# LPC55S16 register map
Vendor: nxp.com; File version: 1.0
CPU: CM33 r2p0, little endian, MPU, FPU, VTOR, 3 interrupt priority bits
Registers are 32-bit, read-write, reset 0x0 unless marked. A register's access mark holds for its fields unless they carry their own. Offsets are from the block's base; [hi:lo] are bit positions; {n}, {i} and the like mark numbered series; 'fields as' and 'values as' point back to an identical list.

## HASHCRYPT — Hash-Crypt peripheral
Base 0x400A4000
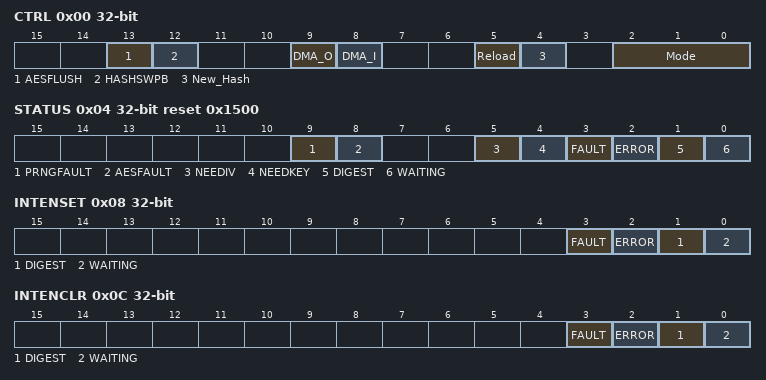
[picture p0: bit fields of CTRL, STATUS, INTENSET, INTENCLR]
0x00 CTRL — Control register to enable and operate Hash and Crypto
  [13] AESFLUSH wo — Flushes the AES engine registers. This bit self clears.
    0=NOFLUSH (Do not flush the AES engine registers.); 1=FLUSH (Flush the AES engine registers.)
  [12] HASHSWPB — If 1, will swap bytes in the word for SHA hashing. The default is byte order (so LSB is 1st byte) but this allows swapping to MSB is 1st such as is shown in SHS spec. For cryptographic swapping, see the CRYPTCFG register.
  [9] DMA_O — Written to 1 to use DMA to drain the digest/output. If both DMA_I and DMA_O are set, the DMA has to know to switch direction and the locations. This can be used for crypto uses.
    0=NOTUSED (DMA is not used. Processor reads the digest/output in response to DIGEST interrupt.)
  [8] DMA_I — Written with 1 to use DMA to fill INDATA. If Hash, will request from DMA for 16 words and then will process the Hash. If Cryptographic, it will load as many words as needed, including key if not already loaded. It will then request again. Normal model is that the DMA interrupts the processor when its length expires. Note that if the processor will write the key and optionally IV, it should not enable this until it has done so. Otherwise, the DMA will be expected to load those for the 1st block (when needed).
    0=NOT_USED (DMA is not used. Processor writes the necessary words when WAITING is set (interrupts), unless AHB Master is used.); 1=PUSH (DMA will push in the data.)
  [5] Reload — If 1, allows the SHA RELOAD registers to be used. This is used to save a partial Hash Digest (e.g. when need to run AES) and then reload it later for continuation.
    1=RELOAD (Allow RELOAD registers to be used.)
  [4] New_Hash wo — Written with 1 when starting a new Hash/Crypto. It self clears. Note that the WAITING Status bit will clear for a cycle during the initialization from New=1.
    1=START (Starts a new Hash/Crypto and initializes the Digest/Result.)
  [2:0] Mode — The operational mode to use, or 0 if none. Note that the CONFIG register will indicate if specific modes beyond SHA1 and SHA2-256 are available.
    0=DISABLED; 1=SHA1 (SHA1 is enabled); 2=SHA2_256 (SHA2-256 is enabled); 4=AES (AES if available (see also CRYPTCFG register for more controls))
0x04 STATUS reset 0x1500 (reset mask 0x3F3737) — Indicates status of Hash peripheral.
  [9] PRNGFAULT ro — PRNG fault status
    0=NO_FAULT (No PRNG fault has occurred.); 1=FAULT (A PRNG fault has occurred.)
  [8] AESFAULT ro — AES fault status
    0=NO_FAULT (No AES fault has occurred.); 1=FAULT (An AES fault has occurred.)
  [5] NEEDIV ro — Indicates the block wants an IV/NONE to be written in (set along with WAITING)
    0=NOT_NEED (No IV/Nonce is needed, either because written already or because not needed.); 1=NEED (IV/Nonce is needed and INDATA/ALIAS will be accepted as IV/Nonce. Will also set WAITING.)
  [4] NEEDKEY ro — Indicates the block wants the key to be written in (set along with WAITING)
    0=NOT_NEED (No Key is needed and writes will not be treated as Key); 1=NEED (Key is needed and INDATA/ALIAS will be accepted as Key. Will also set WAITING.)
  [3] FAULT ro — Indicates if an AES or PRNG fault has occurred
    0=NO_FAULT (No AES or PRNG fault has occurred.); 1=FAULT (An AES or PRNG fault has occurred.)
  [2] ERROR write-1-clears — If 1, an error occurred. For normal uses, this is due to an attempted overrun: INDATA was written when it was not appropriate. For Master cases, this is an AHB bus error; the COUNT field will indicate which block it was on.
    0=NO_ERROR; 1=ERROR (An error occurred since last cleared (written 1 to clear).)
  [1] DIGEST ro — For Hash, if 1 then a DIGEST is ready and waiting and there is no active next block already started. For Cryptographic uses, this will be set for each block processed, indicating OUTDATA (and OUTDATA2 if larger output) contains the next value to read out. This is cleared when any data is written, when New is written, for Cryptographic uses when the last word is read out, or when the block is disabled.
    0=NOT_READY (No Digest is ready); 1=READY (Digest is ready. Application may read it or may write more data)
  [0] WAITING ro — If 1, the block is waiting for more data to process.
    0=NOT_WAITING (Not waiting for data - may be disabled or may be busy. Note that for cryptographic uses, this is not set if IsLast is set nor will it set until at least 1 word is read of the output.); 1=WAITING (Waiting for data to be written in (16 words))
0x08 INTENSET — Write 1 to enable interrupts; reads back with which are set.
  [3] FAULT — Indicates if should interrupt on an AES or PRNG fault as indicated in the STATUS register
    0=NO_INTERRUPT (No interrupt on an AES or PRNG fault); 1=INTERRUPT (Interrupt on an AES or PRNG fault)
  [2] ERROR — Indicates if should interrupt on an ERROR (as defined in Status)
    0=NO_INTERRUPT (Will not interrupt on Error.); 1=INTERRUPT (Will interrupt on Error (until cleared).)
  [1] DIGEST — Indicates if should interrupt when Digest (or Outdata) is ready (completed a hash/crypto or completed a full sequence).
    0=NO_INTERRUPT (Will not interrupt when Digest is ready); 1=INTERRUPT (Will interrupt when Digest is ready. Interrupt cleared by writing more data, starting a new Hash, or disabling (done).)
  [0] WAITING — Indicates if should interrupt when waiting for data input.
    0=NO_INTERRUPT (Will not interrupt when waiting.); 1=INTERRUPT (Will interrupt when waiting)
0x0C INTENCLR reset not defined write-1-clears — Write 1 to clear interrupts.
  [3] FAULT write-1-clears — Write 1 to clear mask.
  [2] ERROR write-1-clears — Write 1 to clear mask.
  [1] DIGEST write-1-clears — Write 1 to clear mask.
  [0] WAITING write-1-clears — Write 1 to clear mask.
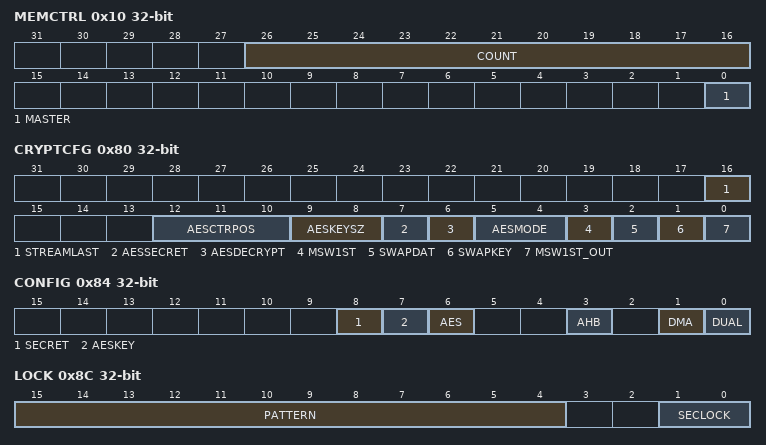
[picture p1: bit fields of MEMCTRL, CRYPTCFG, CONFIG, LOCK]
0x10 MEMCTRL — Setup Master to access memory (if available)
  [26:16] COUNT — Number of 512-bit (128-bit if AES, except 1st block which may include key and IV) blocks to copy starting at MEMADDR. This register will decrement after each block is copied, ending in 0. For Hash, the DIGEST interrupt will occur when it reaches 0. Fro AES, the DIGEST/OUTDATA interrupt will occur on ever block. If a bus error occurs, it will stop with this field set to the block that failed. 0:Done - nothing to process. 1 to 2K: Number of 512-bit (or 128bit) blocks to hash.
  [0] MASTER — Enables mastering.
    0=NOT_USED (Mastering is not used and the normal DMA or Interrupt based model is used with INDATA.); 1=ENABLED (Mastering is enabled and DMA and INDATA should not be used.)
0x14 MEMADDR — Address to start memory access from (if available).
  [31:0] BASE — Address base to start copying from, word aligned (so bits 1:0 must be 0). This field will advance as it processes the words. If it fails with a bus error, the register will contain the failing word. N:Address in Flash or RAM space; RAM only as mapped in this part. May also be able to address SPIFI.
0x20 INDATA wo reset not defined — Input of 16 words at a time to load up buffer.
  [31:0] DATA — Write next word in little-endian form. The hash requires big endian word data, but this block swaps the bytes automatically. That is, SHA assumes the data coming in is treated as bytes (e.g. "abcd") and since the ARM core will treat "abcd" as a word as 0x64636261, the block will swap the word to restore into big endian.
{0x24+4i} ALIAS[{i}] (i=0..6) wo reset not defined — Aliases to allow writing words in a burst.
  fields as INDATA
{0x40+4i} DIGEST0[{i}] (i=0..7) ro — Result digest (when status says so): Is 1st 5 words if SHA1 used Is all 8 words if SHA2 used Is all 8 words if crypto or SHA512
  [31:0] DIGEST — One word of the Digest or output. Note that only 1st 4 are populated for AES and 1st 5 are populated for SHA1.
0x80 CRYPTCFG — Crypto settings for AES and Salsa and ChaCha
  [16] STREAMLAST — Is 1 if last stream block. If not 1, then the engine will compute the next "hash".
  [12:10] AESCTRPOS — Halfword position of 16b counter in IV if AESMODE is CTR (position is fixed for Salsa and ChaCha). Only supports 16b counter, so application must control any additional bytes if using more. The 16-bit counter is read from the IV and incremented by 1 each time. Any other use CTR should use ECB directly and do its own XOR and so on.
  [9:8] AESKEYSZ — Sets the AES key size
    0=BITS_128 (128 bit key); 1=BITS_192 (192 bit key); 2=BITS_256 (256 bit key)
  [7] AESSECRET — Selects the Hidden Secret key vs. User key, if provided. If security levels are used, only the highest level is permitted to select this.
    0=NORMAL_WAY (User key provided in normal way); 1=HIDDEN_WAY (Secret key provided in hidden way by HW)
  [6] AESDECRYPT — AES ECB direction. Only encryption used if CTR mode or manual modes such as CFB
    0=ENCRYPT; 1=DECRYPT
  [5:4] AESMODE — AES Cipher mode to use if plain AES
    0=ECB (ECB - used as is); 1=CBC (CBC mode (see details on IV/nonce)); 2=CTR (CTR mode (see details on IV/nonce). See also AESCTRPOS.)
  [3] MSW1ST — If 1, load of key, IV, and data is MSW 1st for AES. Else, the words are little endian. Note: only if allowed by configuration.
  [2] SWAPDAT — If 1, will SWAP the data and IV inputs (bytes in each word).
  [1] SWAPKEY — If 1, will Swap the key input (bytes in each word).
  [0] MSW1ST_OUT — If 1, OUTDATA0 will be read Most significant word 1st for AES. Else it will be read in normal little endian - Least significant word 1st. Note: only if allowed by configuration.
0x84 CONFIG reset not defined — Returns the configuration of this block in this chip - indicates what services are available.
  [8] SECRET ro — 1 if AES Secret key available
  [7] AESKEY ro — 1 if AES 192 and 256 also included
  [6] AES ro — 1 if AES 128 included
  [3] AHB ro — 1 if AHB Master is enabled
  [1] DMA ro — 1 if DMA is connected
  [0] DUAL ro — 1 if 2 x 512 bit buffers, 0 if only 1 x 512 bit
0x8C LOCK — Lock register allows locking to the current security level or unlocking by the lock holding level.
  [15:4] PATTERN — Must write 0xA75 to change lock state. A75:Pattern needed to change bits 1:0
  [1:0] SECLOCK — Write 1 to secure-lock this block (if running in a security state). Write 0 to unlock. If locked already, may only write if at same or higher security level as lock. Reads as: 0 if unlocked, else 1, 2, 3 to indicate security level it is locked at. NOTE: this and ID are the only readable registers if locked and current state is lower than lock level.
    0=UNLOCK (Unlocks, so block is open to all. But, AHB Master will only issue non-secure requests.); 1=LOCK (Locks to the current security level. AHB Master will issue requests at this level.)
{0x90+4i} MASK[{i}] (i=0..3) wo reset not defined — Allows Application to write a random mask for ICB use. Normally only a new one on each system reset (including power up).
  [31:0] MASK — A random word.
{0xA0+4i} RELOAD[{i}] (i=0..7) wo reset not defined — The WO digest-reload registers may be written with a saved Hash digest, to allow continuation from where left off. These registers may only be written if the Reload field in CTRL is 1. If SHA1, only the 1st 5 are used.
  [31:0] DIGEST — SHA Digest word to reload.
0xD0 PRNG_SEED wo — PRNG random input value used as an entropy source
  [31:0] PRNG_SEED — Random input value used as an entropy source
0xD8 PRNG_OUT ro reset not defined — Provide random number.
